# STM32H7A3xxQ register map
File version: 1.0
Registers are 32-bit, read-write, reset 0x0 unless marked. A register's access mark holds for its fields unless they carry their own. Offsets are from the block's base; [hi:lo] are bit positions; {n}, {i} and the like mark numbered series.

## DLYB_SDMMC2 — Delay Block DLYB
Base 0x48022800
Same registers: DLYB_OCTOSPI1 0x52006000, DLYB_SDMMC1 0x52008000, DLYB_OCTOSPI2 0x5200B000
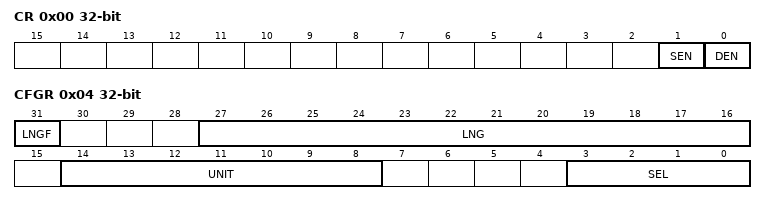
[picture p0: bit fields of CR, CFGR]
0x00 CR — DELAY BLOCK control register
  [1] SEN — Sampler length enable
  [0] DEN — Delay Block enable
0x04 CFGR — DELAY BLOCK configuration register
  [31] LNGF — Length valid flag
  [27:16] LNG — Delay line length value[11:0]
  [14:8] UNIT — Delay Defines the delay of a Unit delay cell[6:0]
  [3:0] SEL — Select the phase for the Output clock[3:0]

## BDMA1
Base 0x48022C00
Same registers: BDMA2 0x58025400
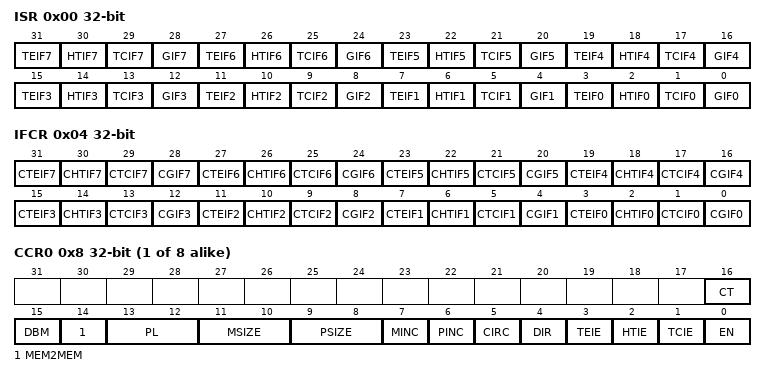
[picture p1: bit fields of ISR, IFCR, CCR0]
0x00 ISR — DMA interrupt status register
  [4n+3] TEIF{n} (n=0..7) — Channel {n} Transfer Error flag
  [4n+2] HTIF{n} (n=0..7) — Channel {n} Half Transfer flag
  [4n+1] TCIF{n} (n=0..7) — Channel {n} Transfer Complete flag
  [4n] GIF{n} (n=0..7) — Channel {n} Global interrupt flag
0x04 IFCR — DMA interrupt flag clear register
  [4n+3] CTEIF{n} (n=0..7) — Channel {n} Transfer Error clear
  [4n+2] CHTIF{n} (n=0..7) — Channel {n} Half Transfer clear
  [4n+1] CTCIF{n} (n=0..7) — Channel {n} Transfer Complete clear
  [4n] CGIF{n} (n=1..7) — Channel {n} Global interrupt clear
  [0] CGIF0 — Channel 0 Global interrupt clearr
{0x8+0x14*i} CCR{i} (i=0..7) — DMA channel x configuration register
  [16] CT — Memory to memory mode
  [15] DBM — Memory to memory mode
  [14] MEM2MEM — Memory to memory mode
  [13:12] PL — PL[1:0] bits(Channel Priority level)
  [11:10] MSIZE — MSIZE[1:0] bits (Memory size)
  [9:8] PSIZE — PSIZE[1:0] bits (Peripheral size)
  [7] MINC — Memory increment mode
  [6] PINC — Peripheral increment mode
  [5] CIRC — Circular mode
  [4] DIR — Data transfer direction
  [3] TEIE — Transfer error interrupt enable
  [2] HTIE — Half Transfer interrupt enable
  [1] TCIE — Transfer complete interrupt enable
  [0] EN — Channel enable
{0xC+0x14*i} CNDTR{i} (i=0..7) — DMA channel x number of data register
  [15:0] NDT — Number of data to Transfer
{0x10+0x14*i} CPAR{i} (i=0..7) — DMA channel x peripheral address register
  [31:0] PA — Peripheral Address
{0x14+0x14*i} CM0AR{i} (i=0..7) — DMA channel x memory 0 address register
  [31:0] MA — Memory Address
{0x18+0x14*i} CM1AR{i} (i=0..7) — DMA channel x memory 1 address register
  [31:0] MA — Memory Address

## WWDG1 — Window WATCHDOG
Base 0x50003000
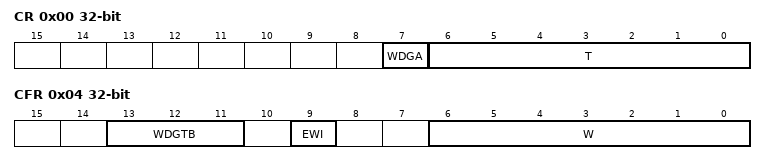
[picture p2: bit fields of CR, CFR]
0x00 CR — WWDG Control register
  [7] WDGA — Activation bit
  [6:0] T — T[6:0] bits (7-Bit counter (MSB to LSB))
0x04 CFR — WWDG Configuration register
  [13:11] WDGTB — WDGTB[2:0] bits (Timer Base)
    0=PRESCALER_1 (WWDG counter clock = (PCLK1/4096)/1); 1=PRESCALER_2 (WWDG counter clock = (PCLK1/4096)/2); 2=PRESCALER_4 (WWDG counter clock = (PCLK1/4096)/4); 3=PRESCALER_8 (WWDG counter clock = (PCLK1/4096)/8); 4=PRESCALER_16 (WWDG counter clock = (PCLK1/4096)/16); 5=PRESCALER_32 (WWDG counter clock = (PCLK1/4096)/32); 6=PRESCALER_64 (WWDG counter clock = (PCLK1/4096)/64); 7=PRESCALER_128 (WWDG counter clock = (PCLK1/4096)/128)
  [9] EWI — Early Wakeup Interrupt
  [6:0] W — W[6:0] bits (7-bit window value)
0x08 SR — WWDG Status register
  [0] EWIF — Early Wakeup Interrupt Flag

## GPV — Global Programmer View
Base 0x51000000
0x1FD0 AXI_PERIPH_ID_4 — AXI interconnect - peripheral ID4 register
{0x1FC0+4i} AXI_PERIPH_ID_{i} (i=5..7) — Reserved
{0x1FE0+4i} AXI_PERIPH_ID_{i} (i=0..3) — AXI interconnect - peripheral ID{i} register
{0x1FF0+4i} AXI_COMP_ID_{i} (i=0..3) — AXI interconnect - component ID{i} register
{0x1008+0x1000*i} AXI_TARG{i}_FN_MOD_ISS_BM (i=1..10) — AXI interconnect - TARG {i} bus matrix issuing functionality register
0x2024 AXI_TARG1_FN_MOD2 — AXI interconnect - TARG 1 bus matrix functionality 2 register
0x202C AXI_TARG1_FN_MOD_LB — AXI interconnect - TARG 1 long burst functionality modification register
0x2108 AXI_TARG1_FN_MOD — AXI interconnect - TARG 1 issuing functionality modification register
0x3024 AXI_TARG2_FN_MOD2 — AXI interconnect - TARG 2 bus matrix functionality 2 register
0x302C AXI_TARG2_FN_MOD_LB — AXI interconnect - TARG 2 long burst functionality modification register
0x3108 AXI_TARG2_FN_MOD — AXI interconnect - TARG 2 issuing functionality modification register
{0x1024+0x1000*i} AXI_TARG{i}_FN_MOD2 (i=7..10) — AXI interconnect - TARG {i} bus matrix functionality 2 register
0x802C AXI_TARG7_FN_MOD_LB — AXI interconnect - TARG 7 long burst functionality modification register
{0x1108+0x1000*i} AXI_TARG{i}_FN_MOD (i=7..10) — AXI interconnect - TARG {i} issuing functionality modification register
0xC02C AXI_TARG10_FN_MOD_LB — AXI interconnect - TARG 10 long burst functionality modification register
0x42024 AXI_INI1_FN_MOD2 — AXI interconnect - INI 1 functionality modification 2 register
0x42028 AXI_INI1_FN_MOD_AHB — AXI interconnect - INI 1 AHB functionality modification register
{0x41100+0x1000*i} AXI_INI{i}_READ_QOS (i=1..7) — AXI interconnect - INI {i} read QoS register
{0x41104+0x1000*i} AXI_INI{i}_WRITE_QOS (i=1..7) — AXI interconnect - INI {i} write QoS register
{0x41108+0x1000*i} AXI_INI{i}_FN_MOD (i=1..7) — AXI interconnect - INI {i} issuing functionality modification register
0x44024 AXI_INI3_FN_MOD2 — AXI interconnect - INI 3 functionality modification 2 register
0x44028 AXI_INI3_FN_MOD_AHB — AXI interconnect - INI 3 AHB functionality modification register
0x48024 AXI_INI7_FN_MOD2 — AXI interconnect - INI 7 functionality modification 2 register
0x48028 AXI_INI7_FN_MOD_AHB — AXI interconnect - INI 7 AHB functionality modification register
